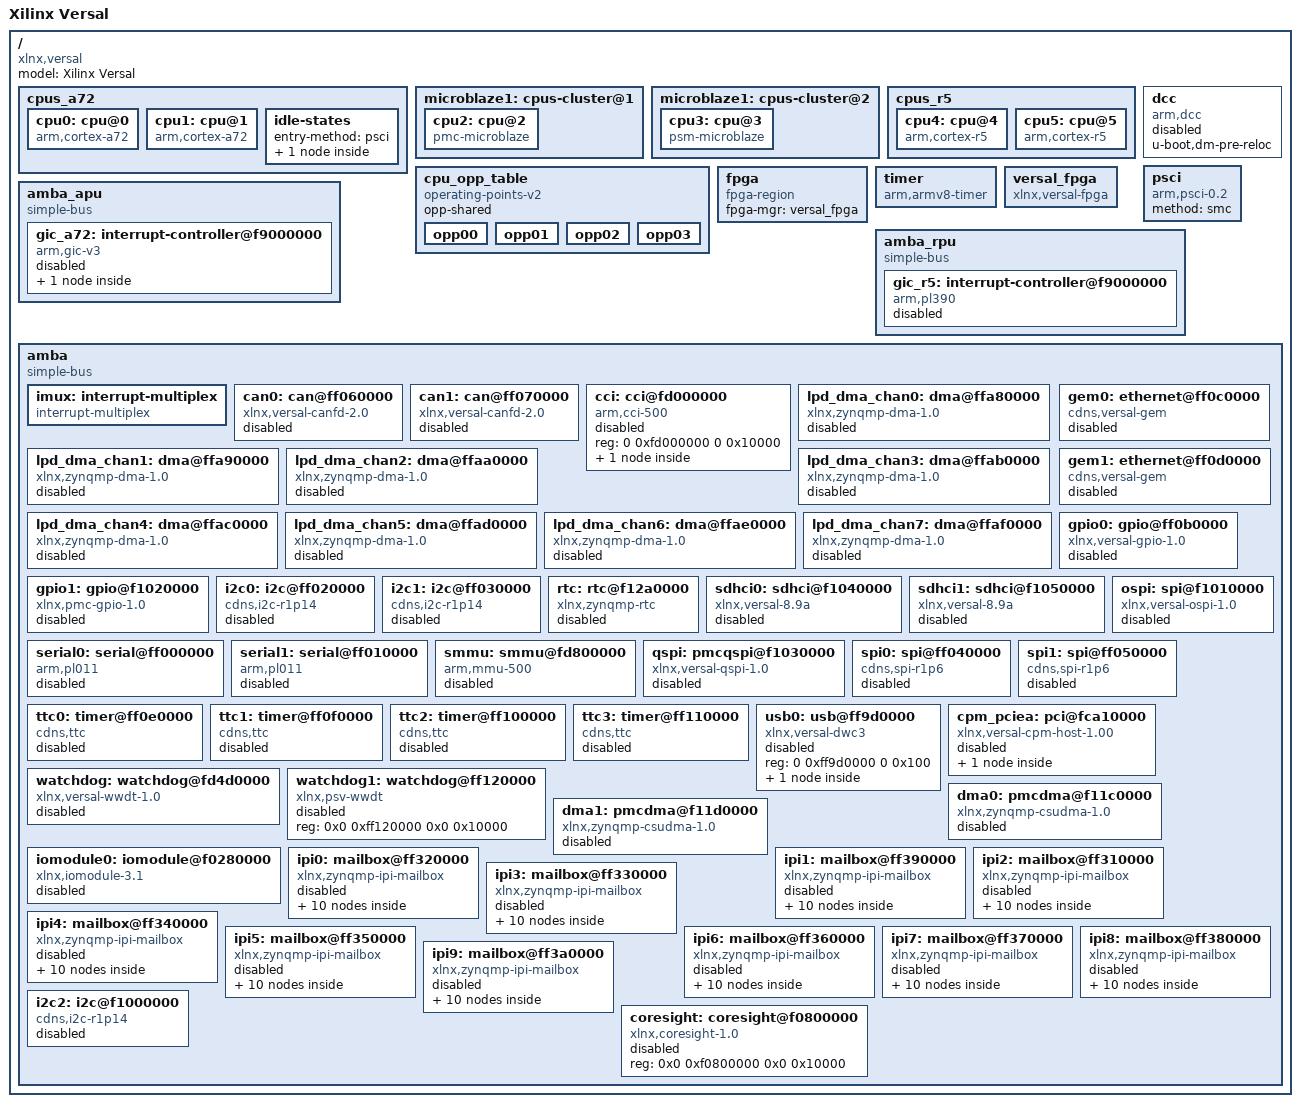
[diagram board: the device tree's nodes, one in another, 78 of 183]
// SPDX-License-Identifier: GPL-2.0
/*
 * dts file for Xilinx Versal
 *
 * (C) Copyright 2017 - 2019, Xilinx, Inc.
 *
 * Michal Simek <michal.simek@xilinx.com>
 */

/dts-v1/;

/ {
	compatible = "xlnx,versal";
	#address-cells = <2>;
	#size-cells = <2>;
	model = "Xilinx Versal";

	cpus_a72: cpus_a72 {
		#address-cells = <1>;
		#size-cells = <0>;

		cpu0: cpu@0 {
			compatible = "arm,cortex-a72", "arm,armv8";
			device_type = "cpu";
			enable-method = "psci";
			operating-points-v2 = <&cpu_opp_table>;
			reg = <0>;
			cpu-idle-states = <&CPU_SLEEP_0>;
		};

		cpu1: cpu@1 {
			compatible = "arm,cortex-a72", "arm,armv8";
			device_type = "cpu";
			enable-method = "psci";
			operating-points-v2 = <&cpu_opp_table>;
			reg = <1>;
			cpu-idle-states = <&CPU_SLEEP_0>;
		};
		idle-states {
			entry-method = "psci";

			CPU_SLEEP_0: cpu-sleep-0 {
				compatible = "arm,idle-state";
				arm,psci-suspend-param = <0x40000000>;
				local-timer-stop;
				entry-latency-us = <300>;
				exit-latency-us = <600>;
				min-residency-us = <10000>;
			};
		};

	};
	microblaze1: cpus-cluster@1 {
		#address-cells = <1>;
		#size-cells = <0>;
                cpu2: cpu@2 {
                        compatible = "pmc-microblaze";
                        device_type = "cpu";
                        reg = <0x2>;
                        operating-points-v2 = <&cpu_opp_table>;
                };
	};
	microblaze1: cpus-cluster@2 {
		#address-cells = <1>;
		#size-cells = <0>;
                cpu3: cpu@3 {
                        compatible = "psm-microblaze";
                        device_type = "cpu";
                        reg = <0x3>;
                        operating-points-v2 = <&cpu_opp_table>;
                };

	};

	cpus_r5: cpus_r5 {
		#address-cells = <1>;
		#size-cells = <0>;
                cpu4: cpu@4 {
                        compatible = "arm,cortex-r5";
                        device_type = "cpu";
                        reg = <0x4>;
                        operating-points-v2 = <&cpu_opp_table>;
                };

                cpu5: cpu@5 {
                        compatible = "arm,cortex-r5";
                        device_type = "cpu";
                        reg = <0x5>;
                        operating-points-v2 = <&cpu_opp_table>;
                };
	};

	cpu_opp_table: cpu_opp_table {
		compatible = "operating-points-v2";
		opp-shared;
		opp00 {
			opp-hz = /bits/ 64 <1199999988>;
			opp-microvolt = <1000000>;
			clock-latency-ns = <500000>;
		};
		opp01 {
			opp-hz = /bits/ 64 <599999994>;
			opp-microvolt = <1000000>;
			clock-latency-ns = <500000>;
		};
		opp02 {
			opp-hz = /bits/ 64 <399999996>;
			opp-microvolt = <1000000>;
			clock-latency-ns = <500000>;
		};
		opp03 {
			opp-hz = /bits/ 64 <299999997>;
			opp-microvolt = <1000000>;
			clock-latency-ns = <500000>;
		};
	};

	dcc: dcc {
		compatible = "arm,dcc";
		status = "disabled";
		u-boot,dm-pre-reloc;
	};

	fpga: fpga {
		compatible = "fpga-region";
		fpga-mgr = <&versal_fpga>;
		#address-cells = <2>;
		#size-cells = <2>;
	};

	psci: psci {
		compatible = "arm,psci-0.2";
		method = "smc";
	};

	timer: timer {
		compatible = "arm,armv8-timer";
		interrupt-parent = <&imux>;
		interrupts = <1 13 4>,
			     <1 14 4>,
			     <1 11 4>,
			     <1 10 4>;
	};

	versal_fpga: versal_fpga {
		compatible = "xlnx,versal-fpga";
	};

	amba_apu: amba_apu {
		compatible = "simple-bus";
		#address-cells = <2>;
		#size-cells = <2>;
		ranges;

		gic_a72: interrupt-controller@f9000000 {
			compatible = "arm,gic-v3";
			#interrupt-cells = <3>;
			#address-cells = <2>;
			#size-cells = <2>;
			ranges;
			reg = <0 0xf9000000 0 0x80000>, /* GICD */
			      <0 0xf9080000 0 0x80000>; /* GICR */
			interrupt-controller;
			interrupt-parent = <&gic_a72>;
			interrupts = <1 9 4>;
			status = "disabled";

			gic_its: gic-its@f9020000 {
				compatible = "arm,gic-v3-its";
				msi-controller;
				msi-cells = <1>;
				reg = <0 0xf9020000 0 0x20000>;
			};
		};
	};
	amba_rpu: amba_rpu {
		compatible = "simple-bus";
		#address-cells = <0x2>;
		#size-cells = <0x2>;
		ranges;

		gic_r5: interrupt-controller@f9000000 {
			compatible = "arm,pl390";
			#interrupt-cells = <3>;
			interrupt-controller;
			status = "disabled";
			reg = <0x0 0xf9000000 0x0 0x1000 0x0 0xf9000000 0x0 0x100>;
		};
	};

	amba: amba {
		compatible = "simple-bus";
		#address-cells = <2>;
		#size-cells = <2>;
		ranges;
		interrupt-parent = <&imux>;
		u-boot,dm-pre-reloc;

		/* Proxy Interrupt Controller */
		imux: interrupt-multiplex {
			compatible = "interrupt-multiplex";
			#address-cells = <0x0>;
			#interrupt-cells = <3>;
			interrupt-controller;
			interrupt-parent = <&gic_a72>, <&gic_r5>;
			/* mask for address cells, mask for interrupt cells of the children */
			interrupt-map-mask = <0x0 0xffff 0x0>;
			/* 1:1 mapping of all interrupts to gic_a72 and gic_r5 */
			/* child address cells, child interrupt cells, parent, parent interrupt cells */
			interrupt-map = <0x0 0x14 0x0 &gic_a72 0x0 0x14 0x1>,
			                <0x0 0x15 0x0 &gic_a72 0x0 0x15 0x1>,
			                <0x0 0x6a 0x0 &gic_a72 0x0 0x6a 0x4>,
			                <0x0 0x3c 0x0 &gic_a72 0x0 0x3c 0x4>,
			                <0x0 0x3d 0x0 &gic_a72 0x0 0x3d 0x4>,
			                <0x0 0x3e 0x0 &gic_a72 0x0 0x3e 0x4>,
			                <0x0 0x3f 0x0 &gic_a72 0x0 0x3f 0x4>,
			                <0x0 0x40 0x0 &gic_a72 0x0 0x40 0x4>,
			                <0x0 0x41 0x0 &gic_a72 0x0 0x41 0x4>,
			                <0x0 0x42 0x0 &gic_a72 0x0 0x42 0x4>,
			                <0x0 0x43 0x0 &gic_a72 0x0 0x43 0x4>,
			                <0x0 0x38 0x0 &gic_a72 0x0 0x38 0x4>,
			                <0x0 0x3a 0x0 &gic_a72 0x0 0x3a 0x4>,
			                <0x0 0xd  0x0 &gic_a72 0x0 0xd 0x4>,
			                <0x0 0x7a 0x0 &gic_a72 0x0 0x7a 0x4>,
			                <0x0 0xe  0x0 &gic_a72 0x0 0xe 0x4>,
			                <0x0 0xf  0x0 &gic_a72 0x0 0xf 0x4>,
			                <0x0 0x8e 0x0 &gic_a72 0x0 0x8e 0x4>,
			                <0x0 0x8f 0x0 &gic_a72 0x0 0x8f 0x4>,
			                <0x0 0x7e 0x0 &gic_a72 0x0 0x7e 0x4>,
			                <0x0 0x80 0x0 &gic_a72 0x0 0x80 0x4>,
			                <0x0 0x12 0x0 &gic_a72 0x0 0x12 0x4>,
			                <0x0 0x13 0x0 &gic_a72 0x0 0x13 0x4>,
			                <0x0 0x6b 0x0 &gic_a72 0x0 0x6b 0x4>,
			                <0x0 0x7c 0x0 &gic_a72 0x0 0x7c 0x4>,
			                <0x0 0x7d 0x0 &gic_a72 0x0 0x7d 0x4>,
			                <0x0 0x10 0x0 &gic_a72 0x0 0x10 0x4>,
			                <0x0 0x11 0x0 &gic_a72 0x0 0x11 0x4>,
			                <0x0 0x16 0x0 &gic_a72 0x0 0x16 0x4>,
			                <0x0 0x1a 0x0 &gic_a72 0x0 0x1a 0x4>,
			                <0x0 0x4a 0x0 &gic_a72 0x0 0x4a 0x4>,
			                <0x0 0x48 0x0 &gic_a72 0x0 0x48 0x4>,
			                <0x0 0x1e 0x0 &gic_a72 0x0 0x1e 0x4>,
			                <0x0 0x1f 0x0 &gic_a72 0x0 0x1f 0x4>,
			                <0x0 0x83 0x0 &gic_a72 0x0 0x83 0x4>,
			                <0x0 0x84 0x0 &gic_a72 0x0 0x84 0x4>,
			                <0x0 0x14 0x0 &gic_r5 0x0 0x14 0x1>,
			                <0x0 0x15 0x0 &gic_r5 0x0 0x15 0x1>,
			                <0x0 0x6a 0x0 &gic_r5 0x0 0x6a 0x4>,
			                <0x0 0x3c 0x0 &gic_r5 0x0 0x3c 0x4>,
			                <0x0 0x3d 0x0 &gic_r5 0x0 0x3d 0x4>,
			                <0x0 0x3e 0x0 &gic_r5 0x0 0x3e 0x4>,
			                <0x0 0x3f 0x0 &gic_r5 0x0 0x3f 0x4>,
			                <0x0 0x40 0x0 &gic_r5 0x0 0x40 0x4>,
			                <0x0 0x41 0x0 &gic_r5 0x0 0x41 0x4>,
			                <0x0 0x42 0x0 &gic_r5 0x0 0x42 0x4>,
			                <0x0 0x43 0x0 &gic_r5 0x0 0x43 0x4>,
			                <0x0 0x38 0x0 &gic_r5 0x0 0x38 0x4>,
			                <0x0 0x3a 0x0 &gic_r5 0x0 0x3a 0x4>,
			                <0x0 0xd  0x0 &gic_r5 0x0 0xd 0x4>,
			                <0x0 0x7a 0x0 &gic_r5 0x0 0x7a 0x4>,
			                <0x0 0xe  0x0 &gic_r5 0x0 0xe 0x4>,
			                <0x0 0xf  0x0 &gic_r5 0x0 0xf 0x4>,
			                <0x0 0x8e 0x0 &gic_r5 0x0 0x8e 0x4>,
			                <0x0 0x8f 0x0 &gic_r5 0x0 0x8f 0x4>,
			                <0x0 0x7e 0x0 &gic_r5 0x0 0x7e 0x4>,
			                <0x0 0x80 0x0 &gic_r5 0x0 0x80 0x4>,
			                <0x0 0x12 0x0 &gic_r5 0x0 0x12 0x4>,
			                <0x0 0x13 0x0 &gic_r5 0x0 0x13 0x4>,
			                <0x0 0x6b 0x0 &gic_r5 0x0 0x6b 0x4>,
			                <0x0 0x7c 0x0 &gic_r5 0x0 0x7c 0x4>,
			                <0x0 0x7d 0x0 &gic_r5 0x0 0x7d 0x4>,
			                <0x0 0x10 0x0 &gic_r5 0x0 0x10 0x4>,
			                <0x0 0x11 0x0 &gic_r5 0x0 0x11 0x4>,
			                <0x0 0x16 0x0 &gic_r5 0x0 0x16 0x4>,
			                <0x0 0x1a 0x0 &gic_r5 0x0 0x1a 0x4>,
			                <0x0 0x4a 0x0 &gic_r5 0x0 0x4a 0x4>,
			                <0x0 0x48 0x0 &gic_r5 0x0 0x48 0x4>,
			                <0x0 0x1e 0x0 &gic_r5 0x0 0x1e 0x4>,
			                <0x0 0x1f 0x0 &gic_r5 0x0 0x1f 0x4>,
			                <0x0 0x83 0x0 &gic_r5 0x0 0x83 0x4>,
			                <0x0 0x84 0x0 &gic_r5 0x0 0x84 0x4>;
		};

		can0: can@ff060000 {
			compatible = "xlnx,versal-canfd-2.0";
			status = "disabled";
			reg = <0 0xff060000 0 0x6000>;
			interrupts = <0 20 1>;
			interrupt-parent = <&imux>;
			clock-names = "can_clk", "s_axi_aclk";
			rx-fifo-depth = <0x40>;
			tx-mailbox-count = <0x20>;
		};

		can1: can@ff070000 {
			compatible = "xlnx,versal-canfd-2.0";
			status = "disabled";
			reg = <0 0xff070000 0 0x6000>;
			interrupts = <0 21 1>;
			interrupt-parent = <&imux>;
			clock-names = "can_clk", "s_axi_aclk";
			rx-fifo-depth = <0x40>;
			tx-mailbox-count = <0x20>;
		};

		cci: cci@fd000000 {
			compatible = "arm,cci-500";
			status = "disabled";
			reg = <0 0xfd000000 0 0x10000>;
			ranges = <0 0 0xfd000000 0xa0000>;
			#address-cells = <1>;
			#size-cells = <1>;
			cci_pmu: pmu@10000 {
				compatible = "arm,cci-500-pmu,r0";
				reg = <0x10000 0x90000>;
				interrupt-parent = <&imux>;
				interrupts = <0 106 4>,
					     <0 106 4>,
					     <0 106 4>,
					     <0 106 4>,
					     <0 106 4>,
					     <0 106 4>,
					     <0 106 4>,
					     <0 106 4>,
					     <0 106 4>;
			};
		};

		lpd_dma_chan0: dma@ffa80000 {
			compatible = "xlnx,zynqmp-dma-1.0";
			status = "disabled";
			reg = <0 0xffa80000 0 0x1000>;
			interrupts = <0 60 4>;
			interrupt-parent = <&imux>;
			clock-names = "clk_main", "clk_apb";
			#stream-id-cells = <1>;
			/* iommus = <&smmu 0x210>; */
			xlnx,bus-width = <64>;
			xlnx,dma-type = <1>;
			/* dma-coherent; */
		};

		lpd_dma_chan1: dma@ffa90000 {
			compatible = "xlnx,zynqmp-dma-1.0";
			status = "disabled";
			reg = <0 0xffa90000 0 0x1000>;
			interrupts = <0 61 4>;
			interrupt-parent = <&imux>;
			clock-names = "clk_main", "clk_apb";
			#stream-id-cells = <1>;
			/* iommus = <&smmu 0x212>; */
			xlnx,bus-width = <64>;
			xlnx,dma-type = <1>;
			/* dma-coherent; */
		};

		lpd_dma_chan2: dma@ffaa0000 {
			compatible = "xlnx,zynqmp-dma-1.0";
			status = "disabled";
			reg = <0 0xffaa0000 0 0x1000>;
			interrupts = <0 62 4>;
			interrupt-parent = <&imux>;
			clock-names = "clk_main", "clk_apb";
			#stream-id-cells = <1>;
			/* iommus = <&smmu 0x214>; */
			xlnx,bus-width = <64>;
			xlnx,dma-type = <1>;
			/* dma-coherent; */
		};


		lpd_dma_chan3: dma@ffab0000 {
			compatible = "xlnx,zynqmp-dma-1.0";
			status = "disabled";
			reg = <0 0xffab0000 0 0x1000>;
			interrupts = <0 63 4>;
			interrupt-parent = <&imux>;
			clock-names = "clk_main", "clk_apb";
			#stream-id-cells = <1>;
			/* iommus = <&smmu 0x216>; */
			xlnx,bus-width = <64>;
			xlnx,dma-type = <1>;
			/* dma-coherent; */
		};

		lpd_dma_chan4: dma@ffac0000 {
			compatible = "xlnx,zynqmp-dma-1.0";
			status = "disabled";
			reg = <0 0xffac0000 0 0x1000>;
			interrupts = <0 64 4>;
			interrupt-parent = <&imux>;
			clock-names = "clk_main", "clk_apb";
			#stream-id-cells = <1>;
			/* iommus = <&smmu 0x218>; */
			xlnx,bus-width = <64>;
			xlnx,dma-type = <1>;
			/* dma-coherent; */
		};

		lpd_dma_chan5: dma@ffad0000 {
			compatible = "xlnx,zynqmp-dma-1.0";
			status = "disabled";
			reg = <0 0xffad0000 0 0x1000>;
			interrupts = <0 65 4>;
			interrupt-parent = <&imux>;
			clock-names = "clk_main", "clk_apb";
			#stream-id-cells = <1>;
			/* iommus = <&smmu 0x21a>; */
			xlnx,bus-width = <64>;
			xlnx,dma-type = <1>;
			/* dma-coherent; */
		};

		lpd_dma_chan6: dma@ffae0000 {
			compatible = "xlnx,zynqmp-dma-1.0";
			status = "disabled";
			reg = <0 0xffae0000 0 0x1000>;
			interrupts = <0 66 4>;
			interrupt-parent = <&imux>;
			clock-names = "clk_main", "clk_apb";
			#stream-id-cells = <1>;
			/* iommus = <&smmu 0x21c>; */
			xlnx,bus-width = <64>;
			xlnx,dma-type = <1>;
			/* dma-coherent; */
		};

		lpd_dma_chan7: dma@ffaf0000 {
			compatible = "xlnx,zynqmp-dma-1.0";
			status = "disabled";
			reg = <0 0xffaf0000 0 0x1000>;
			interrupt-parent = <&imux>;
			interrupts = <0 67 4>;
			clock-names = "clk_main", "clk_apb";
			#stream-id-cells = <1>;
			/* iommus = <&smmu 0x21e>; */
			xlnx,bus-width = <64>;
			xlnx,dma-type = <1>;
			/* dma-coherent; */
		};

		gem0: ethernet@ff0c0000 {
			compatible = "cdns,versal-gem";
			status = "disabled";
			reg = <0 0xff0c0000 0 0x1000>;
			interrupt-parent = <&imux>;
			interrupts = <0 56 4>, <0 56 4>;
			clock-names = "pclk", "hclk", "tx_clk", "rx_clk", "tsu_clk";
			#stream-id-cells = <1>;
			/* iommus = <&smmu 0x234>; */
			/* dma-coherent; */
			#address-cells = <1>;
			#size-cells = <0>;
		};

		gem1: ethernet@ff0d0000 {
			compatible = "cdns,versal-gem";
			status = "disabled";
			reg = <0 0xff0d0000 0 0x1000>;
			interrupt-parent = <&imux>;
			interrupts = <0 58 4>, <0 58 4>;
			clock-names = "pclk", "hclk", "tx_clk", "rx_clk", "tsu_clk";
			#stream-id-cells = <1>;
			/* iommus = <&smmu 0x235>; */
			/* dma-coherent; */
			#address-cells = <1>;
			#size-cells = <0>;
		};


		gpio0: gpio@ff0b0000 {
			compatible = "xlnx,versal-gpio-1.0";
			status = "disabled";
			reg = <0 0xff0b0000 0 0x1000>;
			interrupt-parent = <&imux>;
			interrupts = <0 13 4>;
			#gpio-cells = <2>;
			gpio-controller;
			#interrupt-cells = <2>;
			interrupt-controller;
		};

		gpio1: gpio@f1020000 {
			compatible = "xlnx,pmc-gpio-1.0";
			status = "disabled";
			reg = <0 0xf1020000 0 0x1000>;
			interrupt-parent = <&imux>;
			interrupts = <0 122 4>;
			#gpio-cells = <2>;
			gpio-controller;
			#interrupt-cells = <2>;
			interrupt-controller;
		};

		i2c0: i2c@ff020000 {
			compatible = "cdns,i2c-r1p14", "cdns,i2c-r1p10";
			status = "disabled";
			reg = <0 0xff020000 0 0x1000>;
			interrupt-parent = <&imux>;
			interrupts = <0 14 4>;
			clock-frequency = <400000>;
			#address-cells = <1>;
			#size-cells = <0>;
		};

		i2c1: i2c@ff030000 {
			compatible = "cdns,i2c-r1p14", "cdns,i2c-r1p10";
			status = "disabled";
			reg = <0 0xff030000 0 0x1000>;
			interrupt-parent = <&imux>;
			interrupts = <0 15 4>;
			clock-frequency = <400000>;
			#address-cells = <1>;
			#size-cells = <0>;
		};

		rtc: rtc@f12a0000 {
			compatible = "xlnx,zynqmp-rtc";
			status = "disabled";
			reg = <0 0xf12a0000 0 0x100>;
			interrupt-parent = <&imux>;
			interrupt-names = "alarm", "sec";
			interrupts = <0 142 4>, <0 143 4>;
			calibration = <0x8000>;
		};

		sdhci0: sdhci@f1040000 {
			compatible = "xlnx,versal-8.9a", "arasan,sdhci-8.9a";
			status = "disabled";
			reg = <0 0xf1040000 0 0x10000>;
			interrupt-parent = <&imux>;
			interrupts = <0 126 4>, <0 126 4>;
			clock-names = "clk_xin", "clk_ahb";
			xlnx,device_id = <0>;
			#stream-id-cells = <1>;
			#clock-cells = <1>;
			clock-output-names = "clk_out_sd0", "clk_in_sd0";
			/* iommus = <&smmu 0x242>; */
			/* dma-coherent; */
		};

		sdhci1: sdhci@f1050000 {
			compatible = "xlnx,versal-8.9a", "arasan,sdhci-8.9a";
			status = "disabled";
			reg = <0 0xf1050000 0 0x10000>;
			interrupt-parent = <&imux>;
			interrupts = <0 128 4>, <0 128 4>;
			clock-names = "clk_xin", "clk_ahb";
			xlnx,device_id = <1>;
			#stream-id-cells = <1>;
			#clock-cells = <1>;
			clock-output-names = "clk_out_sd1", "clk_in_sd1";
			/* iommus = <&smmu 0x243>; */
			/* dma-coherent; */
		};

		serial0: serial@ff000000 {
			compatible = "arm,pl011", "arm,sbsa-uart";
			status = "disabled";
			reg = <0 0xff000000 0 0x1000>;
			interrupt-parent = <&imux>;
			interrupts = <0 18 4>;
			clock-names = "uart_clk", "apb_clk";
			current-speed = <115200>;
			u-boot,dm-pre-reloc;
		};

		serial1: serial@ff010000 {
			compatible = "arm,pl011", "arm,sbsa-uart";
			status = "disabled";
			reg = <0 0xff010000 0 0x1000>;
			interrupt-parent = <&imux>;
			interrupts = <0 19 4>;
			clock-names = "uart_clk", "apb_clk";
			current-speed = <115200>;
			u-boot,dm-pre-reloc;
		};

		smmu: smmu@fd800000 {
			compatible = "arm,mmu-500";
			status = "disabled";
			reg = <0 0xfd800000 0 0x40000>;
			stream-match-mask = <0x7c00>;
			#iommu-cells = <1>;
			#global-interrupts = <1>;
			interrupt-parent = <&imux>;
			interrupts = <0 107 4>,
				     <0 107 4>, <0 107 4>, <0 107 4>, <0 107 4>,
				     <0 107 4>, <0 107 4>, <0 107 4>, <0 107 4>,
				     <0 107 4>, <0 107 4>, <0 107 4>, <0 107 4>,
				     <0 107 4>, <0 107 4>, <0 107 4>, <0 107 4>,
				     <0 107 4>, <0 107 4>, <0 107 4>, <0 107 4>,
				     <0 107 4>, <0 107 4>, <0 107 4>, <0 107 4>,
				     <0 107 4>, <0 107 4>, <0 107 4>, <0 107 4>,
				     <0 107 4>, <0 107 4>, <0 107 4>, <0 107 4>;
		};

		ospi: spi@f1010000 {
			compatible = "xlnx,versal-ospi-1.0", "cadence,qspi", "cdns,qspi-nor";
			status = "disabled";
			reg = <0 0xf1010000 0 0x10000 0 0xc0000000 0 0x20000000>;
			interrupts = <0 124 4>, <0 124 4>;
			interrupt-parent = <&imux>;
			clock-names = "ref_clk", "pclk";
			cdns,fifo-depth = <256>;
			cdns,fifo-width = <4>;
			cdns,is-dma = <1>;
			cdns,is-stig-pgm = <1>;
			cdns,trigger-address = <0xC0000000>;
			#stream-id-cells = <1>;
			#address-cells = <1>;
			#size-cells = <0>;
		};

		qspi: pmcqspi@f1030000 {
			compatible = "xlnx,versal-qspi-1.0";
			status = "disabled";
			reg = <0 0xf1030000 0 0x1000>;
			interrupts = <0 125 4>, <0 125 4>;
			interrupt-parent = <&imux>;
			clock-names = "ref_clk", "pclk";
			#stream-id-cells = <1>;
			/* iommus = <&smmu 0x244>; */
			/* dma-coherent; */
			#address-cells = <1>;
			#size-cells = <0>;
		};

		spi0: spi@ff040000 {
			compatible = "cdns,spi-r1p6";
			status = "disabled";
			reg = <0 0xff040000 0 0x1000>;
			interrupts = <0 16 4>;
			interrupt-parent = <&imux>;
			clock-names = "ref_clk", "pclk";
			#address-cells = <1>;
			#size-cells = <0>;
		};

		spi1: spi@ff050000 {
			compatible = "cdns,spi-r1p6";
			status = "disabled";
			reg = <0 0xff050000 0 0x1000>;
			interrupts = <0 17 4>;
			interrupt-parent = <&imux>;
			clock-names = "ref_clk", "pclk";
			#address-cells = <1>;
			#size-cells = <0>;
		};

                ttc0: timer@ff0e0000 {
                        compatible = "cdns,ttc";
                        status = "disabled";
                        interrupts = <0 37 4>, <0 38 4>, <0 39 4>;
                        reg = <0x0 0xff0e0000 0x0 0x1000>;
                        timer-width = <32>;
                };
 
                ttc1: timer@ff0f0000 {
                        compatible = "cdns,ttc";
                        status = "disabled";
                        interrupts = <0 40 4>, <0 41 4>, <0 42 4>;
                        reg = <0x0 0xff0f0000 0x0 0x1000>;
                        timer-width = <32>;
                };

                ttc2: timer@ff100000 {
                        compatible = "cdns,ttc";
                        status = "disabled";
                        interrupts = <0 43 4>, <0 44 4>, <0 45 4>;
                        reg = <0x0 0xff100000 0x0 0x1000>;
                        timer-width = <32>;
                };

                ttc3: timer@ff110000 {
                        compatible = "cdns,ttc";
                        status = "disabled";
                        interrupts = <0 46 4>, <0 47 4>, <0 48 4>;
                        reg = <0x0 0xff110000 0x0 0x1000>;
                        timer-width = <32>;
                };

		usb0: usb@ff9d0000 {
			compatible = "xlnx,versal-dwc3";
			status = "disabled";
			reg = <0 0xff9d0000 0 0x100>;
			clock-names = "bus_clk", "ref_clk";
			ranges;
			#address-cells = <2>;
			#size-cells = <2>;

			dwc3_0: dwc3@fe200000 {
				compatible = "snps,dwc3";
				status = "disabled";
				reg = <0 0xfe200000 0 0x10000>;
				interrupt-names = "dwc_usb3", "otg", "usb-wakeup";
				interrupts = <0 0x16 4>, <0 0x1A 4>, <0x0 0x4a 0x4>;
				interrupt-parent = <&imux>;
				#stream-id-cells = <1>;
				/* iommus = <&smmu 0x230>; */
				snps,dis_u2_susphy_quirk;
				snps,dis_u3_susphy_quirk;
				snps,quirk-frame-length-adjustment = <0x20>;
				snps,refclk_fladj;
				snps,mask_phy_reset;
				/* dma-coherent; */
			};
		};

		cpm_pciea: pci@fca10000 {
			#address-cells = <3>;
			#interrupt-cells = <1>;
			#size-cells = <2>;
			compatible = "xlnx,versal-cpm-host-1.00";
			status = "disabled";
			interrupt-map = <0 0 0 1 &pcie_intc_0 1>,
					<0 0 0 2 &pcie_intc_0 2>,
					<0 0 0 3 &pcie_intc_0 3>,
					<0 0 0 4 &pcie_intc_0 4>;
			interrupt-map-mask = <0 0 0 7>;
			interrupt-parent = <&imux>;
			interrupt-names = "misc";
			interrupts = <0 72 4>;
			ranges = <0x02000000 0x00000000 0xe0000000 0x0 0xe0000000 0x00000000 0x10000000>,
				 <0x43000000 0x00000080 0x00000000 0x00000080 0x00000000 0x00000000 0x80000000>;
			msi-map = <0x0 &gic_its 0x0 0x10000>;
			reg = <0x0 0xfca10000 0x0 0x1000>,
			      <0x6 0x00000000 0x0 0x1000000>;
			reg-names = "cpm_slcr", "cfg";
			pcie_intc_0: pci-interrupt-controller {
				#address-cells = <0>;
				#interrupt-cells = <1>;
				interrupt-controller ;
			};
		};

		watchdog: watchdog@fd4d0000 {
			compatible = "xlnx,versal-wwdt-1.0";
			status = "disabled";
			reg = <0 0xfd4d0000 0 0x10000>;
			timeout-sec = <60>;
		};

		watchdog1: watchdog@ff120000 {
                        compatible = "xlnx,psv-wwdt";
                        status = "disabled";
                        reg = <0x0 0xff120000 0x0 0x10000>;
                };

		dma0: pmcdma@f11c0000 {
			status = "disabled";
			compatible = "xlnx,zynqmp-csudma-1.0";
			interrupt-parent = <&imux>;
			interrupts = <0 86 4>;
			reg = <0x0 0xf11c0000 0x0 0x40000>;
			xlnx,dma-type = <1>;
                };
		
		dma1: pmcdma@f11d0000 {
			status = "disabled";
			compatible = "xlnx,zynqmp-csudma-1.0";
			interrupt-parent = <&imux>;
			interrupts = <0 86 4>;
			reg = <0x0 0xf11d0000 0x0 0x40000>;
			xlnx,dma-type = <2>;
                };

		iomodule0: iomodule@f0280000 {
			status = "disabled";
			compatible = "xlnx,iomodule-3.1";
			reg = <0x0 0xF0280000 0x0 0x1000>, <0xFFFFFFFF 0xFFFFFFFF 0x0 0xE0000>;
			xlnx,intc-has-fast = <0x0>;
			xlnx,intc-base-vectors = <0xF0240000U>;
			xlnx,intc-addr-width = <0x20>;
			xlnx,intc-level-edge = <0x7FFU>;
			xlnx,clock-freq = <100000000U>;
			xlnx,uart-baudrate = <115200U>;
			xlnx,pit-used = <01 01 01 01>;
			xlnx,pit-size = <0x20 0x20 0x20 0x20>;
			xlnx,pit-mask = <0xFFFFFFFF 0xFFFFFFFF 0xFFFFFFFF 0xFFFFFFFF>;
			xlnx,pit-prescaler = <0x9 0x0 0x9 0x0>;
			xlnx,pit-readable = <01 01 01 01>;
			xlnx,gpo-init = <00 00 00 00>;
			xlnx,options = <0x1>;
			xlnx,max-intr-size = <32>;
		};
		
		ipi0: mailbox@ff320000 {
                	status = "disabled";
	                compatible = "xlnx,zynqmp-ipi-mailbox";
        	        interrupt-parent = <&imux>;
			interrupts = <0 59 4>;
                	reg = <0x0 0xFF320000U 0x0 0x20>;
	                xlnx,ipi-bitmask = <0x2>;
        	        xlnx,ipi-id = <1>;
                	#address-cells = <2>;
	                #size-cells = <2>;
        	        xlnx,ipi-target-count = <10>;
                	ranges;

	                ipi0_0: mailbox@0 {
        	                xlnx,ipi-id = <1>;
                	        xlnx,ipi-bitmask = <0x2>;
	                };
        	        ipi0_1: mailbox@1 {
                	        xlnx,ipi-id = <0>;
                        	xlnx,ipi-bitmask = <0x1>;
	                };
        	        ipi0_2: mailbox@2 {
                	        xlnx,ipi-id = <2>;
	                        xlnx,ipi-bitmask = <0x4>;
        	        };
                	ipi0_3: mailbox@3 {
  	                      	xlnx,ipi-id = <3>;
        	              	xlnx,ipi-bitmask = <0x8>;
                	};
	                ipi0_4: mailbox@4 {
        	                xlnx,ipi-id = <4>;
                	        xlnx,ipi-bitmask = <0x10>;
	                };
        	        ipi0_5: mailbox@5 {
	                        xlnx,ipi-id = <5>;
        	                xlnx,ipi-bitmask = <0x20>;
	                };
        	        ipi0_6: mailbox@6 {
                	        xlnx,ipi-id = <6>;
	                        xlnx,ipi-bitmask = <0x40>;
        	        };
        	        ipi0_7: mailbox@7 {
                	        xlnx,ipi-id = <7>;
	                        xlnx,ipi-bitmask = <0x80>;
        	        };
        	        ipi0_8: mailbox@8 {
                	        xlnx,ipi-id = <0xFFFF>;
	                        xlnx,ipi-bitmask = <0x100>;
        	        };
        	        ipi0_9: mailbox@9 {
                	        xlnx,ipi-id = <0xFFFF>;
	                        xlnx,ipi-bitmask = <0x200>;
        	        };
        	};

		ipi1: mailbox@ff390000 {
                	status = "disabled";
	                compatible = "xlnx,zynqmp-ipi-mailbox";
        	        interrupt-parent = <&imux>;
			interrupts = <0 60 4>;
                	reg = <0x0 0xFF390000U 0x0 0x20>;
	                xlnx,ipi-bitmask = <0x100>;
        	        xlnx,ipi-id = <0xFFFF>;
                	#address-cells = <2>;
	                #size-cells = <2>;
        	        xlnx,ipi-target-count = <10>;
                	ranges;

	                ipi1_0: mailbox@0 {
        	                xlnx,ipi-id = <1>;
                	        xlnx,ipi-bitmask = <0x2>;
	                };
        	        ipi1_1: mailbox@1 {
                	        xlnx,ipi-id = <0>;
                        	xlnx,ipi-bitmask = <0x1>;
	                };
        	        ipi1_2: mailbox@2 {
                	        xlnx,ipi-id = <2>;
	                        xlnx,ipi-bitmask = <0x4>;
        	        };
                	ipi1_3: mailbox@3 {
  	                      	xlnx,ipi-id = <3>;
        	              	xlnx,ipi-bitmask = <0x8>;
                	};
	                ipi1_4: mailbox@4 {
        	                xlnx,ipi-id = <4>;
                	        xlnx,ipi-bitmask = <0x10>;
	                };
        	        ipi1_5: mailbox@5 {
	                        xlnx,ipi-id = <5>;
        	                xlnx,ipi-bitmask = <0x20>;
	                };
        	        ipi1_6: mailbox@6 {
                	        xlnx,ipi-id = <6>;
	                        xlnx,ipi-bitmask = <0x40>;
        	        };
        	        ipi1_7: mailbox@7 {
                	        xlnx,ipi-id = <7>;
	                        xlnx,ipi-bitmask = <0x80>;
        	        };
        	        ipi1_8: mailbox@8 {
                	        xlnx,ipi-id = <0xFFFF>;
	                        xlnx,ipi-bitmask = <0x100>;
        	        };
        	        ipi1_9: mailbox@9 {
                	        xlnx,ipi-id = <0xFFFF>;
	                        xlnx,ipi-bitmask = <0x200>;
        	        };
        	};

		ipi2: mailbox@ff310000 {
                	status = "disabled";
	                compatible = "xlnx,zynqmp-ipi-mailbox";
        	        interrupt-parent = <&imux>;
			interrupts = <0 61 4>;
                	reg = <0x0 0xFF310000U 0x0 0x20>;
	                xlnx,ipi-bitmask = <0x1>;
                        xlnx,ipi-id = <0>;
                	#address-cells = <2>;
	                #size-cells = <2>;
        	        xlnx,ipi-target-count = <10>;
                	ranges;

	                ipi2_0: mailbox@0 {
        	                xlnx,ipi-id = <1>;
                	        xlnx,ipi-bitmask = <0x2>;
	                };
        	        ipi2_1: mailbox@1 {
                	        xlnx,ipi-id = <0>;
                        	xlnx,ipi-bitmask = <0x1>;
	                };
        	        ipi2_2: mailbox@2 {
                	        xlnx,ipi-id = <2>;
	                        xlnx,ipi-bitmask = <0x4>;
        	        };
                	ipi2_3: mailbox@3 {
  	                      	xlnx,ipi-id = <3>;
        	              	xlnx,ipi-bitmask = <0x8>;
                	};
	                ipi2_4: mailbox@4 {
        	                xlnx,ipi-id = <4>;
                	        xlnx,ipi-bitmask = <0x10>;
	                };
        	        ipi2_5: mailbox@5 {
	                        xlnx,ipi-id = <5>;
        	                xlnx,ipi-bitmask = <0x20>;
	                };
        	        ipi2_6: mailbox@6 {
                	        xlnx,ipi-id = <6>;
	                        xlnx,ipi-bitmask = <0x40>;
        	        };
        	        ipi2_7: mailbox@7 {
                	        xlnx,ipi-id = <7>;
	                        xlnx,ipi-bitmask = <0x80>;
        	        };
        	        ipi2_8: mailbox@8 {
                	        xlnx,ipi-id = <0xFFFF>;
	                        xlnx,ipi-bitmask = <0x100>;
        	        };
        	        ipi2_9: mailbox@9 {
                	        xlnx,ipi-id = <0xFFFF>;
	                        xlnx,ipi-bitmask = <0x200>;
        	        };
        	};

		ipi3: mailbox@ff330000 {
                	status = "disabled";
	                compatible = "xlnx,zynqmp-ipi-mailbox";
        	        interrupt-parent = <&imux>;
			interrupts = <0 62 4>;
                	reg = <0x0 0xFF330000U 0x0 0x20>;
	                xlnx,ipi-bitmask = <0x4>;
                        xlnx,ipi-id = <2>;
                	#address-cells = <2>;
	                #size-cells = <2>;
        	        xlnx,ipi-target-count = <10>;
                	ranges;

	                ipi3_0: mailbox@0 {
        	                xlnx,ipi-id = <1>;
                	        xlnx,ipi-bitmask = <0x2>;
	                };
        	        ipi3_1: mailbox@1 {
                	        xlnx,ipi-id = <0>;
                        	xlnx,ipi-bitmask = <0x1>;
	                };
        	        ipi3_2: mailbox@2 {
                	        xlnx,ipi-id = <2>;
	                        xlnx,ipi-bitmask = <0x4>;
        	        };
                	ipi3_3: mailbox@3 {
  	                      	xlnx,ipi-id = <3>;
        	              	xlnx,ipi-bitmask = <0x8>;
                	};
	                ipi3_4: mailbox@4 {
        	                xlnx,ipi-id = <4>;
                	        xlnx,ipi-bitmask = <0x10>;
	                };
        	        ipi3_5: mailbox@5 {
	                        xlnx,ipi-id = <5>;
        	                xlnx,ipi-bitmask = <0x20>;
	                };
        	        ipi3_6: mailbox@6 {
                	        xlnx,ipi-id = <6>;
	                        xlnx,ipi-bitmask = <0x40>;
        	        };
        	        ipi3_7: mailbox@7 {
                	        xlnx,ipi-id = <7>;
	                        xlnx,ipi-bitmask = <0x80>;
        	        };
        	        ipi3_8: mailbox@8 {
                	        xlnx,ipi-id = <0xFFFF>;
	                        xlnx,ipi-bitmask = <0x100>;
        	        };
        	        ipi3_9: mailbox@9 {
                	        xlnx,ipi-id = <0xFFFF>;
	                        xlnx,ipi-bitmask = <0x200>;
        	        };
        	};

		ipi4: mailbox@ff340000 {
                	status = "disabled";
	                compatible = "xlnx,zynqmp-ipi-mailbox";
        	        interrupt-parent = <&imux>;
			interrupts = <0 63 4>;
                	reg = <0x0 0xFF340000U 0x0 0x20>;
	                xlnx,ipi-bitmask = <0x8>;
                        xlnx,ipi-id = <3>;
                	#address-cells = <2>;
	                #size-cells = <2>;
        	        xlnx,ipi-target-count = <10>;
                	ranges;

	                ipi4_0: mailbox@0 {
        	                xlnx,ipi-id = <1>;
                	        xlnx,ipi-bitmask = <0x2>;
	                };
        	        ipi4_1: mailbox@1 {
                	        xlnx,ipi-id = <0>;
                        	xlnx,ipi-bitmask = <0x1>;
	                };
        	        ipi4_2: mailbox@2 {
                	        xlnx,ipi-id = <2>;
	                        xlnx,ipi-bitmask = <0x4>;
        	        };
                	ipi4_3: mailbox@3 {
  	                      	xlnx,ipi-id = <3>;
        	              	xlnx,ipi-bitmask = <0x8>;
                	};
	                ipi4_4: mailbox@4 {
        	                xlnx,ipi-id = <4>;
                	        xlnx,ipi-bitmask = <0x10>;
	                };
        	        ipi4_5: mailbox@5 {
	                        xlnx,ipi-id = <5>;
        	                xlnx,ipi-bitmask = <0x20>;
	                };
        	        ipi4_6: mailbox@6 {
                	        xlnx,ipi-id = <6>;
	                        xlnx,ipi-bitmask = <0x40>;
        	        };
        	        ipi4_7: mailbox@7 {
                	        xlnx,ipi-id = <7>;
	                        xlnx,ipi-bitmask = <0x80>;
        	        };
        	        ipi4_8: mailbox@8 {
                	        xlnx,ipi-id = <0xFFFF>;
	                        xlnx,ipi-bitmask = <0x100>;
        	        };
        	        ipi4_9: mailbox@9 {
                	        xlnx,ipi-id = <0xFFFF>;
	                        xlnx,ipi-bitmask = <0x200>;
        	        };
        	};

		ipi5: mailbox@ff350000 {
                	status = "disabled";
	                compatible = "xlnx,zynqmp-ipi-mailbox";
        	        interrupt-parent = <&imux>;
			interrupts = <0 64 4>;
                	reg = <0x0 0xFF350000U 0x0 0x20>;
	                xlnx,ipi-bitmask = <0x10>;
                        xlnx,ipi-id = <4>;
                	#address-cells = <2>;
	                #size-cells = <2>;
        	        xlnx,ipi-target-count = <10>;
                	ranges;

	                ipi5_0: mailbox@0 {
        	                xlnx,ipi-id = <1>;
                	        xlnx,ipi-bitmask = <0x2>;
	                };
        	        ipi5_1: mailbox@1 {
                	        xlnx,ipi-id = <0>;
                        	xlnx,ipi-bitmask = <0x1>;
	                };
        	        ipi5_2: mailbox@2 {
                	        xlnx,ipi-id = <2>;
	                        xlnx,ipi-bitmask = <0x4>;
        	        };
                	ipi5_3: mailbox@3 {
  	                      	xlnx,ipi-id = <3>;
        	              	xlnx,ipi-bitmask = <0x8>;
                	};
	                ipi5_4: mailbox@4 {
        	                xlnx,ipi-id = <4>;
                	        xlnx,ipi-bitmask = <0x10>;
	                };
        	        ipi5_5: mailbox@5 {
	                        xlnx,ipi-id = <5>;
        	                xlnx,ipi-bitmask = <0x20>;
	                };
        	        ipi5_6: mailbox@6 {
                	        xlnx,ipi-id = <6>;
	                        xlnx,ipi-bitmask = <0x40>;
        	        };
        	        ipi5_7: mailbox@7 {
                	        xlnx,ipi-id = <7>;
	                        xlnx,ipi-bitmask = <0x80>;
        	        };
        	        ipi5_8: mailbox@8 {
                	        xlnx,ipi-id = <0xFFFF>;
	                        xlnx,ipi-bitmask = <0x100>;
        	        };
        	        ipi5_9: mailbox@9 {
                	        xlnx,ipi-id = <0xFFFF>;
	                        xlnx,ipi-bitmask = <0x200>;
        	        };
        	};

		ipi6: mailbox@ff360000 {
                	status = "disabled";
	                compatible = "xlnx,zynqmp-ipi-mailbox";
        	        interrupt-parent = <&imux>;
			interrupts = <0 65 4>;
                	reg = <0x0 0xFF360000U 0x0 0x20>;
	                xlnx,ipi-bitmask = <0x20>;
                        xlnx,ipi-id = <0x5>;
                	#address-cells = <2>;
	                #size-cells = <2>;
        	        xlnx,ipi-target-count = <10>;
                	ranges;

	                ipi6_0: mailbox@0 {
        	                xlnx,ipi-id = <1>;
                	        xlnx,ipi-bitmask = <0x2>;
	                };
        	        ipi6_1: mailbox@1 {
                	        xlnx,ipi-id = <0>;
                        	xlnx,ipi-bitmask = <0x1>;
	                };
        	        ipi6_2: mailbox@2 {
                	        xlnx,ipi-id = <2>;
	                        xlnx,ipi-bitmask = <0x4>;
        	        };
                	ipi6_3: mailbox@3 {
  	                      	xlnx,ipi-id = <3>;
        	              	xlnx,ipi-bitmask = <0x8>;
                	};
	                ipi6_4: mailbox@4 {
        	                xlnx,ipi-id = <4>;
                	        xlnx,ipi-bitmask = <0x10>;
	                };
        	        ipi6_5: mailbox@5 {
	                        xlnx,ipi-id = <5>;
        	                xlnx,ipi-bitmask = <0x20>;
	                };
        	        ipi6_6: mailbox@6 {
                	        xlnx,ipi-id = <6>;
	                        xlnx,ipi-bitmask = <0x40>;
        	        };
        	        ipi6_7: mailbox@7 {
                	        xlnx,ipi-id = <7>;
	                        xlnx,ipi-bitmask = <0x80>;
        	        };
        	        ipi6_8: mailbox@8 {
                	        xlnx,ipi-id = <0xFFFF>;
	                        xlnx,ipi-bitmask = <0x100>;
        	        };
        	        ipi6_9: mailbox@9 {
                	        xlnx,ipi-id = <0xFFFF>;
	                        xlnx,ipi-bitmask = <0x200>;
        	        };
        	};

		ipi7: mailbox@ff370000 {
                	status = "disabled";
	                compatible = "xlnx,zynqmp-ipi-mailbox";
        	        interrupt-parent = <&imux>;
			interrupts = <0 66 4>;
                	reg = <0x0 0xFF370000U 0x0 0x20>;
	                xlnx,ipi-bitmask = <0x40>;
                        xlnx,ipi-id = <0x6>;
                	#address-cells = <2>;
	                #size-cells = <2>;
        	        xlnx,ipi-target-count = <10>;
                	ranges;

	                ipi7_0: mailbox@0 {
        	                xlnx,ipi-id = <1>;
                	        xlnx,ipi-bitmask = <0x2>;
	                };
        	        ipi7_1: mailbox@1 {
                	        xlnx,ipi-id = <0>;
                        	xlnx,ipi-bitmask = <0x1>;
	                };
        	        ipi7_2: mailbox@2 {
                	        xlnx,ipi-id = <2>;
	                        xlnx,ipi-bitmask = <0x4>;
        	        };
                	ipi7_3: mailbox@3 {
  	                      	xlnx,ipi-id = <3>;
        	              	xlnx,ipi-bitmask = <0x8>;
                	};
	                ipi7_4: mailbox@4 {
        	                xlnx,ipi-id = <4>;
                	        xlnx,ipi-bitmask = <0x10>;
	                };
        	        ipi7_5: mailbox@5 {
	                        xlnx,ipi-id = <5>;
        	                xlnx,ipi-bitmask = <0x20>;
	                };
        	        ipi7_6: mailbox@6 {
                	        xlnx,ipi-id = <6>;
	                        xlnx,ipi-bitmask = <0x40>;
        	        };
        	        ipi7_7: mailbox@7 {
                	        xlnx,ipi-id = <7>;
	                        xlnx,ipi-bitmask = <0x80>;
        	        };
        	        ipi7_8: mailbox@8 {
                	        xlnx,ipi-id = <0xFFFF>;
	                        xlnx,ipi-bitmask = <0x100>;
        	        };
        	        ipi7_9: mailbox@9 {
                	        xlnx,ipi-id = <0xFFFF>;
	                        xlnx,ipi-bitmask = <0x200>;
        	        };
        	};

		ipi8: mailbox@ff380000 {
                	status = "disabled";
	                compatible = "xlnx,zynqmp-ipi-mailbox";
        	        interrupt-parent = <&imux>;
			interrupts = <0 67 4>;
                	reg = <0x0 0xFF380000U 0x0 0x20>;
	                xlnx,ipi-bitmask = <0x80>;
                        xlnx,ipi-id = <0x7>;
                	#address-cells = <2>;
	                #size-cells = <2>;
        	        xlnx,ipi-target-count = <10>;
                	ranges;

	                ipi8_0: mailbox@0 {
        	                xlnx,ipi-id = <1>;
                	        xlnx,ipi-bitmask = <0x2>;
	                };
        	        ipi8_1: mailbox@1 {
                	        xlnx,ipi-id = <0>;
                        	xlnx,ipi-bitmask = <0x1>;
	                };
        	        ipi8_2: mailbox@2 {
                	        xlnx,ipi-id = <2>;
	                        xlnx,ipi-bitmask = <0x4>;
        	        };
                	ipi8_3: mailbox@3 {
  	                      	xlnx,ipi-id = <3>;
        	              	xlnx,ipi-bitmask = <0x8>;
                	};
	                ipi8_4: mailbox@4 {
        	                xlnx,ipi-id = <4>;
                	        xlnx,ipi-bitmask = <0x10>;
	                };
        	        ipi8_5: mailbox@5 {
	                        xlnx,ipi-id = <5>;
        	                xlnx,ipi-bitmask = <0x20>;
	                };
        	        ipi8_6: mailbox@6 {
                	        xlnx,ipi-id = <6>;
	                        xlnx,ipi-bitmask = <0x40>;
        	        };
        	        ipi8_7: mailbox@7 {
                	        xlnx,ipi-id = <7>;
	                        xlnx,ipi-bitmask = <0x80>;
        	        };
        	        ipi8_8: mailbox@8 {
                	        xlnx,ipi-id = <0xFFFF>;
	                        xlnx,ipi-bitmask = <0x100>;
        	        };
        	        ipi8_9: mailbox@9 {
                	        xlnx,ipi-id = <0xFFFF>;
	                        xlnx,ipi-bitmask = <0x200>;
        	        };
        	};

		ipi9: mailbox@ff3a0000 {
                	status = "disabled";
	                compatible = "xlnx,zynqmp-ipi-mailbox";
        	        interrupt-parent = <&imux>;
			interrupts = <0 68 4>;
                	reg = <0x0 0xFF3A0000U 0x0 0x20>;
	                xlnx,ipi-bitmask = <0x200>;
                        xlnx,ipi-id = <0xFFFF>;
                	#address-cells = <2>;
	                #size-cells = <2>;
        	        xlnx,ipi-target-count = <10>;
                	ranges;

	                ipi9_0: mailbox@0 {
        	                xlnx,ipi-id = <1>;
                	        xlnx,ipi-bitmask = <0x2>;
	                };
        	        ipi9_1: mailbox@1 {
                	        xlnx,ipi-id = <0>;
                        	xlnx,ipi-bitmask = <0x1>;
	                };
        	        ipi9_2: mailbox@2 {
                	        xlnx,ipi-id = <2>;
	                        xlnx,ipi-bitmask = <0x4>;
        	        };
                	ipi9_3: mailbox@3 {
  	                      	xlnx,ipi-id = <3>;
        	              	xlnx,ipi-bitmask = <0x8>;
                	};
	                ipi9_4: mailbox@4 {
        	                xlnx,ipi-id = <4>;
                	        xlnx,ipi-bitmask = <0x10>;
	                };
        	        ipi9_5: mailbox@5 {
	                        xlnx,ipi-id = <5>;
        	                xlnx,ipi-bitmask = <0x20>;
	                };
        	        ipi9_6: mailbox@6 {
                	        xlnx,ipi-id = <6>;
	                        xlnx,ipi-bitmask = <0x40>;
        	        };
        	        ipi9_7: mailbox@7 {
                	        xlnx,ipi-id = <7>;
	                        xlnx,ipi-bitmask = <0x80>;
        	        };
        	        ipi9_8: mailbox@8 {
                	        xlnx,ipi-id = <0xFFFF>;
	                        xlnx,ipi-bitmask = <0x100>;
        	        };
        	        ipi9_9: mailbox@9 {
                	        xlnx,ipi-id = <0xFFFF>;
	                        xlnx,ipi-bitmask = <0x200>;
        	        };
        	};

		i2c2: i2c@f1000000 {
			compatible = "cdns,i2c-r1p14", "cdns,i2c-r1p10";
			status = "disabled";
			reg = <0 0xf1000000 0 0x1000>;
			clock-frequency = <400000>;
			#address-cells = <1>;
			#size-cells = <0>;
		};

		coresight: coresight@f0800000 {
			compatible = "xlnx,coresight-1.0";
			status = "disabled";
			reg = <0x0 0xf0800000 0x0 0x10000>;
		};

	};

};
